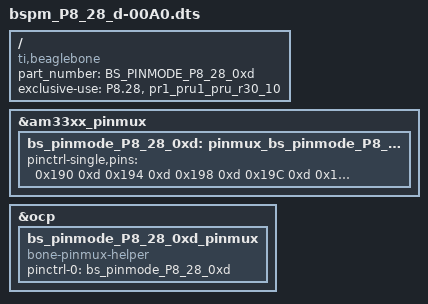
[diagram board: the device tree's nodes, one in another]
/*
 * This is a template-generated file from BoneScript
 * echo bspm_P8_28_d > /sys/devices/platform/bone_capemgr/slots
 */

/dts-v1/;
/plugin/;

/{
    compatible = "ti,beaglebone", "ti,beaglebone-black";
    part_number = "BS_PINMODE_P8_28_0xd";

    exclusive-use =
        "P8.28",
        "pr1_pru1_pru_r30_10";

    fragment@0 {
        target = <&am33xx_pinmux>;
        __overlay__ {
            bs_pinmode_P8_28_0xd: pinmux_bs_pinmode_P8_28_0xd {
                pinctrl-single,pins = <
                    0x190 0xd
                    0x194 0xd
                    0x198 0xd
                    0x19C 0xd
                    0x1A0 0xd
                    0x1A4 0xd
                    0x1A8 0xd
                    0x1AC 0xd
                    0x030 0xe
                    0x034 0xe
                    0x0A0 0xd
                    0x0A4 0xd
                    0x0A8 0xd
                    0x0AC 0xd
                    0x0B0 0xd
                    0x0B4 0xd
                    0x0B8 0xd
                    0x0BC 0xd
                    0x0E0 0xd
                    0x0E4 0xd
                    0x0E8 0xd
                    0x0EC 0xd
                >;
            };
        };
    };

    fragment@1 {
        target = <&ocp>;
        __overlay__ {
            bs_pinmode_P8_28_0xd_pinmux {
                compatible = "bone-pinmux-helper";
                status = "okay";
                pinctrl-names = "default";
                pinctrl-0 = <&bs_pinmode_P8_28_0xd>;
            };
        };
    };
};


